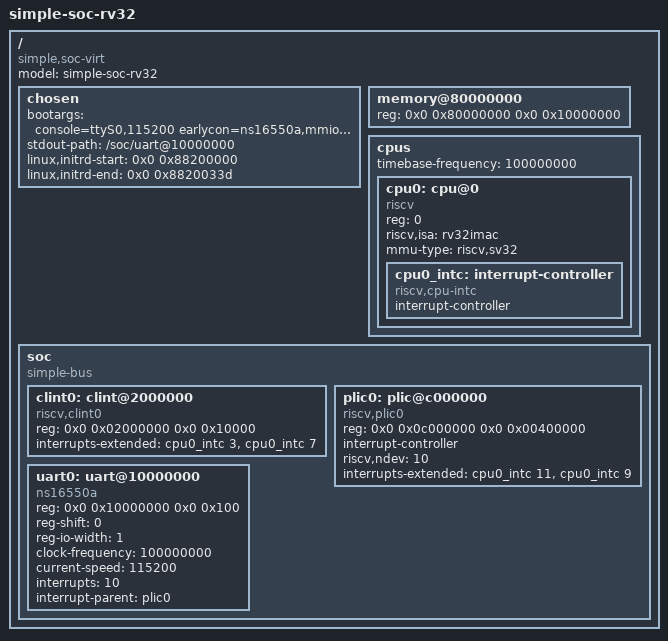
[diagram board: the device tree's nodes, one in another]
/dts-v1/;

/ {
	#address-cells = <2>;
	#size-cells = <2>;
	compatible = "simple,soc-virt";
	model = "simple-soc-rv32";

	chosen {
		bootargs = "console=ttyS0,115200 earlycon=ns16550a,mmio,0x10000000";
		stdout-path = "/soc/uart@10000000";
		linux,initrd-start = <0x0 0x88200000>;
		linux,initrd-end = <0x0 0x8820033d>;
	};

	memory@80000000 {
		device_type = "memory";
		reg = <0x0 0x80000000 0x0 0x10000000>;
	};

	cpus {
		#address-cells = <1>;
		#size-cells = <0>;
		timebase-frequency = <100000000>;

		cpu0: cpu@0 {
			device_type = "cpu";
			reg = <0>;
			status = "okay";
			compatible = "riscv";
			riscv,isa = "rv32imac";
			mmu-type = "riscv,sv32";

			cpu0_intc: interrupt-controller {
				#interrupt-cells = <1>;
				interrupt-controller;
				compatible = "riscv,cpu-intc";
			};
		};
	};

	soc {
		#address-cells = <2>;
		#size-cells = <2>;
		compatible = "simple-bus";
		ranges;

		clint0: clint@2000000 {
			compatible = "riscv,clint0";
			reg = <0x0 0x02000000 0x0 0x10000>;
			interrupts-extended = <&cpu0_intc 3 &cpu0_intc 7>;
		};

		plic0: plic@c000000 {
			compatible = "riscv,plic0";
			reg = <0x0 0x0c000000 0x0 0x00400000>;
			#address-cells = <0>;
			#interrupt-cells = <1>;
			interrupt-controller;
			riscv,ndev = <10>;
			interrupts-extended = <&cpu0_intc 11 &cpu0_intc 9>;
		};

		uart0: uart@10000000 {
			compatible = "ns16550a";
			reg = <0x0 0x10000000 0x0 0x100>;
			reg-shift = <0>;
			reg-io-width = <1>;
			clock-frequency = <100000000>;
			current-speed = <115200>;
			interrupts = <10>;
			interrupt-parent = <&plic0>;
			status = "okay";
		};
	};
};
